# INSTR_CM_CORE_AON register map
Vendor: Texas Instruments
Peripheral module from a debugger description file (folder omap5430_ES2_PUBLIC).
Registers are 32-bit, access per field, reset 0x0 unless marked. A register's access mark holds for its fields unless they carry their own. Offsets are as the file gives them; lines under a group give offsets from that group; [hi:lo] are bit positions; {n}, {i} and the like mark numbered series; 'fields as' and 'values as' point back to an identical list; <NAME> marks a mode.

## INSTR_CM_CORE_AON
0x00 CMI_IDENTICATION_AON ro reset not defined — CM profiling identification register
  [31:0] REVISION — IP revision
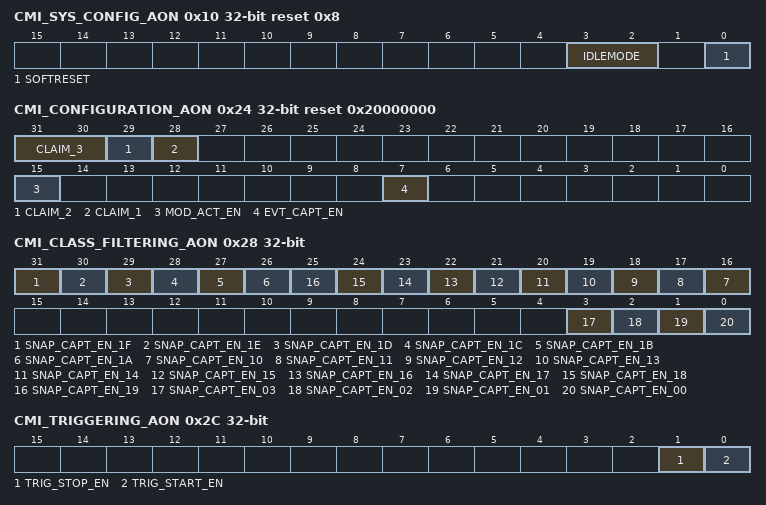
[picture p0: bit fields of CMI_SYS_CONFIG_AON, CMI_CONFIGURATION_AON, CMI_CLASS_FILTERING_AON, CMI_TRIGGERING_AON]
0x10 CMI_SYS_CONFIG_AON reset 0x8 — CM profiling system configuartion register
  [3:2] IDLEMODE rw — Configuration of the local tartget state management mode
  [0] SOFTRESET rw — Software reset
0x14 CMI_STATUS_AON ro reset 0x100 — CM profiling status register
  [8] FIFOEMPTY — CM Profiling buffer empty status 0x0: CM profiling buffer not empty – CM events not yet exported 0x1: CM profiling buffer empty
0x24 CMI_CONFIGURATION_AON reset 0x20000000 — CM profiling configuration register
  [31:30] CLAIM_3 rw — Ownership
  [29] CLAIM_2 rw — Debugger override qualifier
  [28] CLAIM_1 ro — Current owner
  [15] MOD_ACT_EN rw — When HIGH the CM Module Activity collection is enabled
  [7] EVT_CAPT_EN rw — When HIGH the CM events capture is enabled
0x28 CMI_CLASS_FILTERING_AON — CM profiling class filtering register
  [31] SNAP_CAPT_EN_1F rw — Snapshot capture enable - Class-ID = 0x1F
  [30] SNAP_CAPT_EN_1E rw — Snapshot capture enable - Class-ID = 0x1E
  [29] SNAP_CAPT_EN_1D rw — Snapshot capture enable - Class-ID = 0x1D
  [28] SNAP_CAPT_EN_1C rw — Snapshot capture enable - Class-ID = 0x1C
  [27] SNAP_CAPT_EN_1B rw — Snapshot capture enable - Class-ID = 0x1B
  [26] SNAP_CAPT_EN_1A rw — Snapshot capture enable - Class-ID = 0x1A
  [n+6] SNAP_CAPT_EN_{n} rw (n=10..19) — Snapshot capture enable - Class-ID = {0x6+n}
  [3] SNAP_CAPT_EN_03 rw — Snapshot capture enable - Class-ID = 0x03 [0x23]
  [2] SNAP_CAPT_EN_02 rw — Snapshot capture enable - Class-ID = 0x02 [0x22]
  [1] SNAP_CAPT_EN_01 rw — Snapshot capture enable - Class-ID = 0x01 [0x21]
  [0] SNAP_CAPT_EN_00 rw — Snapshot capture enable - Class-ID = 0x00 [0x20]
0x2C CMI_TRIGGERING_AON — CM profiling triggering control register
  [1] TRIG_STOP_EN rw — Enable stop capturing CM events from external trigger detection
  [0] TRIG_START_EN rw — Enable start capturing CM events from external trigger detection
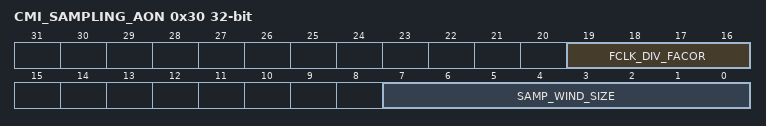
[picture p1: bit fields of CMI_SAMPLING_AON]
0x30 CMI_SAMPLING_AON — CM profiling sampling window register
  [19:16] FCLK_DIV_FACOR rw — FunClk divide factor ranging from 1 to 16
  [7:0] SAMP_WIND_SIZE rw — CM events sampling window size
